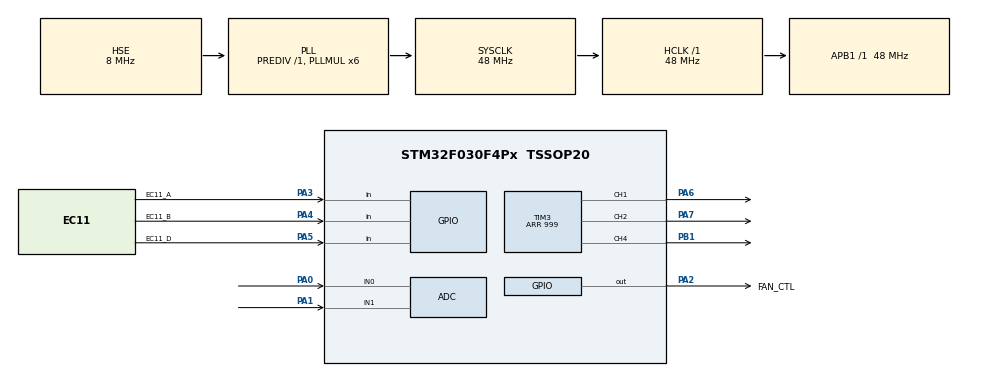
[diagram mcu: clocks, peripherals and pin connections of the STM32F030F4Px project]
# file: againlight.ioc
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ADC.ClockPrescaler=ADC_CLOCK_SYNC_PCLK_DIV4
ADC.ContinuousConvMode=ENABLE
ADC.DMAContinuousRequests=ENABLE
ADC.SamplingTime=ADC_SAMPLETIME_239CYCLES_5
Dma.ADC.0.Direction=DMA_PERIPH_TO_MEMORY
Dma.ADC.0.Instance=DMA1_Channel1
Dma.ADC.0.MemDataAlignment=DMA_MDATAALIGN_HALFWORD
Dma.ADC.0.MemInc=DMA_MINC_ENABLE
Dma.ADC.0.Mode=DMA_CIRCULAR
Dma.ADC.0.PeriphDataAlignment=DMA_PDATAALIGN_HALFWORD
Dma.ADC.0.PeriphInc=DMA_PINC_DISABLE
Dma.ADC.0.Priority=DMA_PRIORITY_LOW
Dma.Request0=ADC
Mcu.Family=STM32F0
Mcu.Name=STM32F030F4Px
Mcu.Package=TSSOP20
NVIC.DMA1_Channel1_IRQn=true\:3\:0\:true\:false\:true\:false\:true\:true
NVIC.TIM1_BRK_UP_TRG_COM_IRQn=true\:0\:0\:false\:false\:true\:true\:true\:true
PA0.Mode=IN0
PA0.Signal=ADC_IN0
PA1.Mode=IN1
PA1.Signal=ADC_IN1
PA13.Mode=Serial_Wire
PA13.Signal=SYS_SWDIO
PA14.Mode=Serial_Wire
PA14.Signal=SYS_SWCLK
PA2.GPIO_Label=FAN_CTL
PA2.Signal=GPIO_Output
PA3.GPIO_Label=EC11_A
PA3.Signal=GPIO_Input
PA4.GPIO_Label=EC11_B
PA4.Signal=GPIO_Input
PA5.GPIO_Label=EC11_D
PA5.Signal=GPIO_Input
PA6.Signal=S_TIM3_CH1
PA7.Signal=S_TIM3_CH2
PB1.Signal=S_TIM3_CH4
PF0-OSC_IN.Mode=HSE-External-Oscillator
PF0-OSC_IN.Signal=RCC_OSC_IN
PF1-OSC_OUT.Mode=HSE-External-Oscillator
PF1-OSC_OUT.Signal=RCC_OSC_OUT
ProjectManager.HeapSize=0x200
ProjectManager.StackSize=0x400
ProjectManager.TargetToolchain=MDK-ARM V5
RCC.AHBFreq_Value=48000000
RCC.APB1Freq_Value=48000000
RCC.APB1TimFreq_Value=48000000
RCC.HCLKFreq_Value=48000000
RCC.PLLMUL=RCC_PLL_MUL6
RCC.PLLSourceVirtual=RCC_PLLSOURCE_HSE
RCC.SYSCLKFreq_VALUE=48000000
RCC.SYSCLKSource=RCC_SYSCLKSOURCE_PLLCLK
SH.S_TIM3_CH1.0=TIM3_CH1,PWM Generation1 CH1
SH.S_TIM3_CH2.0=TIM3_CH2,PWM Generation2 CH2
SH.S_TIM3_CH4.0=TIM3_CH4,PWM Generation4 CH4
TIM1.AutoReloadPreload=TIM_AUTORELOAD_PRELOAD_ENABLE
TIM1.Period=199
TIM1.Prescaler=47
TIM3.AutoReloadPreload=TIM_AUTORELOAD_PRELOAD_ENABLE
TIM3.Channel-PWM\ Generation1\ CH1=TIM_CHANNEL_1
TIM3.Channel-PWM\ Generation2\ CH2=TIM_CHANNEL_2
TIM3.Channel-PWM\ Generation4\ CH4=TIM_CHANNEL_4
TIM3.Period=999
TIM3.Pulse-PWM\ Generation1\ CH1=1
TIM3.Pulse-PWM\ Generation2\ CH2=1
VP_TIM1_VS_ClockSourceINT.Mode=Internal
VP_TIM3_VS_ClockSourceINT.Mode=Internal
board=custom

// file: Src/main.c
/* USER CODE BEGIN Header */
/**
  ******************************************************************************
  * @file           : main.c
  * @brief          : Main program body
  ******************************************************************************
  * @attention
  *
  * Copyright (c) 2026 STMicroelectronics.
  * All rights reserved.
  *
  * This software is licensed under terms that can be found in the LICENSE file
  * in the root directory of this software component.
  * If no LICENSE file comes with this software, it is provided AS-IS.
  *
  ******************************************************************************
  */
/* USER CODE END Header */
#include "main.h"
#include "adc.h"
#include "dma.h"
#include "tim.h"
#include "gpio.h"

/* USER CODE BEGIN Includes */
#include "bsp_program.h"

/* USER CODE END Includes */

void SystemClock_Config(void);

int main(void)
{

  /* MCU Configuration--------------------------------------------------------*/

  /* Reset of all peripherals, Initializes the Flash interface and the Systick. */
  HAL_Init();

  /* Configure the system clock */
  SystemClock_Config();

  /* Initialize all configured peripherals */
  MX_GPIO_Init();
  MX_DMA_Init();
  MX_ADC_Init();
  MX_TIM1_Init();
  MX_TIM3_Init();
  /* USER CODE BEGIN 2 */

	hardware_config();
  /* USER CODE END 2 */

  /* Infinite loop */
  while (1)
  {

  }
}

void SystemClock_Config(void)
{
  RCC_OscInitTypeDef RCC_OscInitStruct = {0};
  RCC_ClkInitTypeDef RCC_ClkInitStruct = {0};

  /** Initializes the RCC Oscillators according to the specified parameters
  * in the RCC_OscInitTypeDef structure.
  */
  RCC_OscInitStruct.OscillatorType = RCC_OSCILLATORTYPE_HSE;
  RCC_OscInitStruct.HSEState = RCC_HSE_ON;
  RCC_OscInitStruct.PLL.PLLState = RCC_PLL_ON;
  RCC_OscInitStruct.PLL.PLLSource = RCC_PLLSOURCE_HSE;
  RCC_OscInitStruct.PLL.PLLMUL = RCC_PLL_MUL6;
  RCC_OscInitStruct.PLL.PREDIV = RCC_PREDIV_DIV1;
  if (HAL_RCC_OscConfig(&RCC_OscInitStruct) != HAL_OK)
  {
    Error_Handler();
  }

  /** Initializes the CPU, AHB and APB buses clocks
  */
  RCC_ClkInitStruct.ClockType = RCC_CLOCKTYPE_HCLK|RCC_CLOCKTYPE_SYSCLK
                              |RCC_CLOCKTYPE_PCLK1;
  RCC_ClkInitStruct.SYSCLKSource = RCC_SYSCLKSOURCE_PLLCLK;
  RCC_ClkInitStruct.AHBCLKDivider = RCC_SYSCLK_DIV1;
  RCC_ClkInitStruct.APB1CLKDivider = RCC_HCLK_DIV1;

  if (HAL_RCC_ClockConfig(&RCC_ClkInitStruct, FLASH_LATENCY_1) != HAL_OK)
  {
    Error_Handler();
  }
}

void Error_Handler(void)
{
  __disable_irq();
  while (1)
  {
  }
}
